# cslr_pwm_001 register map
Vendor: Texas Instruments
Peripheral module from a debugger description file.
Registers are 32-bit, access per field, reset 0x0 unless marked. A register's access mark holds for its fields unless they carry their own. Offsets are as the file gives them; lines under a group give offsets from that group; [hi:lo] are bit positions; {n}, {i} and the like mark numbered series; 'fields as' and 'values as' point back to an identical list; <NAME> marks a mode.

## PWM — Pulse Width Modulator
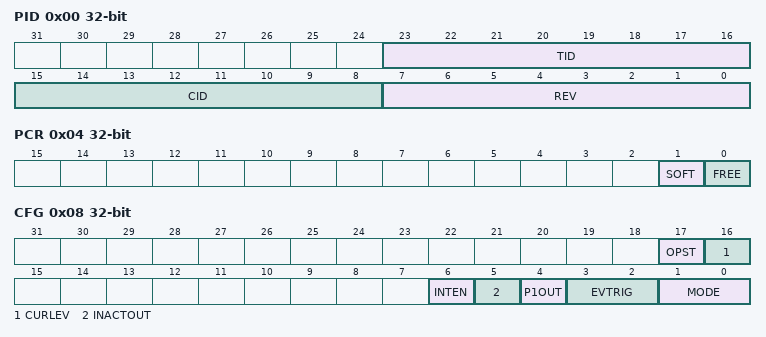
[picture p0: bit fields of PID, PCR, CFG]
0x00 PID ro — PWM Peripheral ID Register
  [23:16] TID — Peripheral type ID
  [15:8] CID — Peripheral class ID
  [7:0] REV — Peripheral revision number
0x04 PCR — PWM Peripheral Control Register
  [1] SOFT ro — Used in conjunction with FREE bit to determine the emulation mode of the PWM. (Fixed at 0)
  [0] FREE rw — Used in conjunction with SOFT bit to determine the emulation mode of the PWM When FREE bit is cleared, SOFT bit selects the PWM mode.
    0=STOP (PWM stops immediately in response to emu_suspend. ( SOFT bit selects the PWM mode and is fixed as zero)); 1=RUN (The PWM runs free regardless of SOFT bit status)
0x08 CFG — PWM Configuration Register
  [17] OPST ro — PWM operation status
    0=IDLE (Idle mode); 1=RUN (Running mode)
  [16] CURLEV ro — PWM output status
    0=LOW; 1=HIGH
  [6] INTEN rw — Interrupt enable
    0=DISABLE (Disable interrupt); 1=ENABLE (Enable interrupt)
  [5] INACTOUT rw — Inactive output level
    0=LOW; 1=HIGH
  [4] P1OUT rw — First phase output level
    0=LOW; 1=HIGH
  [3:2] EVTRIG rw — Event trigger
    0=DISABLE; 1=PEDGE (Positive edge triggered); 2=NEDGE (Negative edge triggered); 3=RSV (Reserved)
  [1:0] MODE rw — Operting mode
    0=DISABLE; 1=OSHOT (One Shot mode); 2=CONT (Continuous mode); 3=RSV (Reserved)
0x0C START — PWM Start Register
  [0] START wo — PWM Start bit
    1=START (Start PWM)
0x10 RPT — PWM Repeat Count Register
  [15:0] RPT rw — One-shot mode repeat count (is RPT + 1)
0x14 PER — PWM Period Register
  [15:0] PER rw — Output period (is PER + 1 clock cycles)
0x18 PH1D — PWM First phase duration Register
  [15:0] PH1D rw — First phase duration (is P1D clock cycles)
